AUTOSAR XML (schema 4-0-3)
package /AlarmSystem/DataTypes
  base type boolean_base: category=BOOLEAN, base-type-size=8, base-type-encoding=BOOLEAN
  impl type Boolean_Imp: category=VALUE, base-type=boolean_base
  app type Boolean_App: category=VALUE, implementation-data-type=Boolean_Imp
  data type mapping set Boolean_DTMS: data-type-map{application-data-type=Boolean_App, implementation-data-type=Boolean_Imp}
package /AlarmSystem/Interfaces
  sender receiver interface AlarmInputs_IF
    data DoorOpen: type=Boolean_App
    data CodeOK: type=Boolean_App
  sender receiver interface AlarmOutputs_IF
    data AlarmOn: type=Boolean_App
package /AlarmSystem/Components
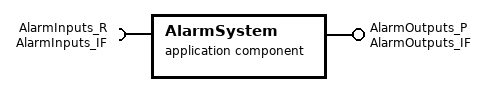
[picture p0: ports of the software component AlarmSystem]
  application sw component type AlarmSystem: category=APPLICATION_SW_COMPONENT_TYPE
    require port AlarmInputs_R: required-interface=AlarmInputs_IF
    provide port AlarmOutputs_P: provided-interface=AlarmOutputs_IF
